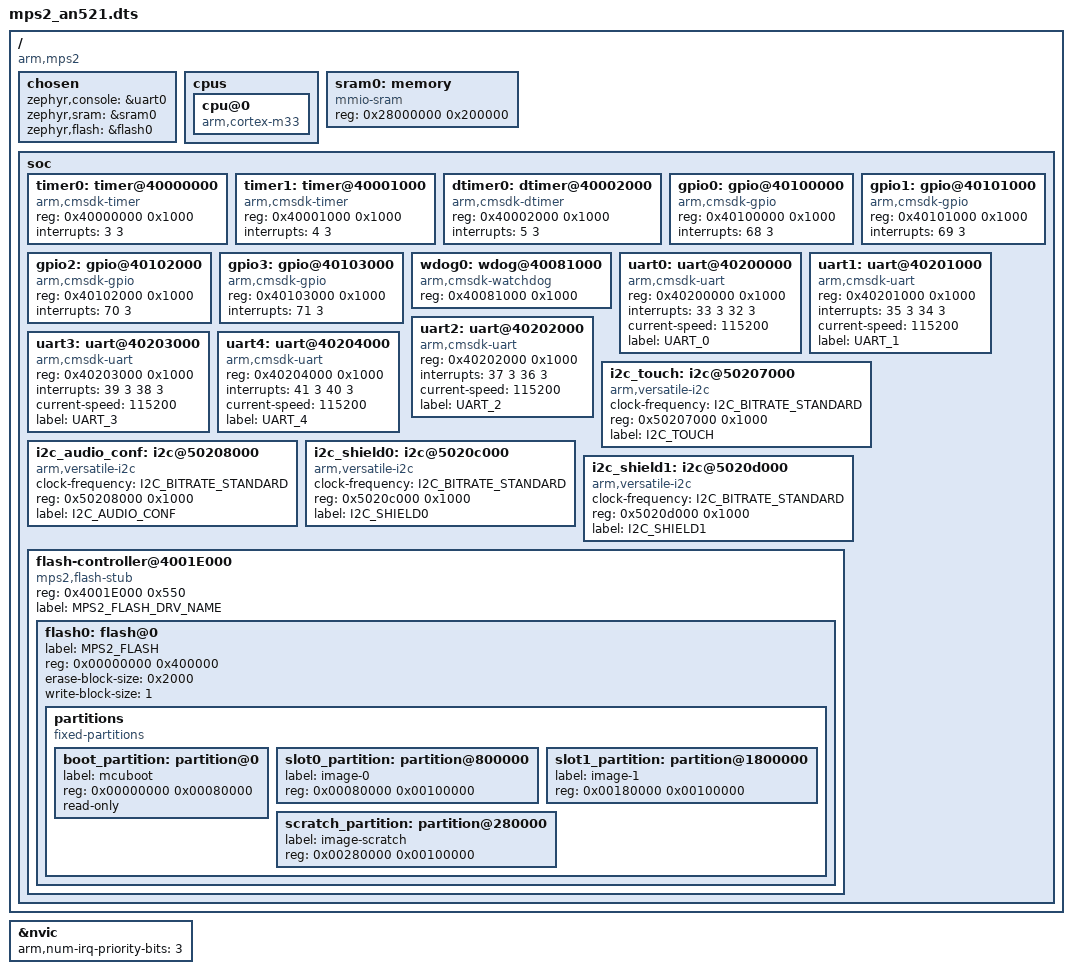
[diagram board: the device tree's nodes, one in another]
/dts-v1/;

#include <arm/armv8-m.dtsi>
#include <dt-bindings/i2c/i2c.h>

/ {
	compatible = "arm,mps2";
	#address-cells = <1>;
	#size-cells = <1>;

	chosen {
		zephyr,console = &uart0;
		zephyr,sram = &sram0;
		zephyr,flash = &flash0;
	};

	cpus {
		cpu@0 {
			compatible = "arm,cortex-m33";
		};
	};

	sram0: memory {
			compatible = "mmio-sram";
			reg = <0x28000000 0x200000>;
	};

	soc {
		timer0: timer@40000000 {
			compatible = "arm,cmsdk-timer";
			reg = <0x40000000 0x1000>;
			interrupts = <3 3>;
		};

		timer1: timer@40001000 {
			compatible = "arm,cmsdk-timer";
			reg = <0x40001000 0x1000>;
			interrupts = <4 3>;
		};

		dtimer0: dtimer@40002000 {
			compatible = "arm,cmsdk-dtimer";
			reg = <0x40002000 0x1000>;
			interrupts = <5 3>;
		};

		gpio0: gpio@40100000 {
			compatible = "arm,cmsdk-gpio";
			reg = <0x40100000 0x1000>;
			interrupts = <68 3>;
		};

		gpio1: gpio@40101000 {
			compatible = "arm,cmsdk-gpio";
			reg = <0x40101000 0x1000>;
			interrupts = <69 3>;
		};

		gpio2: gpio@40102000 {
			compatible = "arm,cmsdk-gpio";
			reg = <0x40102000 0x1000>;
			interrupts = <70 3>;
		};

		gpio3: gpio@40103000 {
			compatible = "arm,cmsdk-gpio";
			reg = <0x40103000 0x1000>;
			interrupts = <71 3>;
		};

		wdog0: wdog@40081000 {
			compatible = "arm,cmsdk-watchdog";
			reg = <0x40081000 0x1000>;
		};

		uart0: uart@40200000 {
			compatible = "arm,cmsdk-uart";
			reg = <0x40200000 0x1000>;
			interrupts = <33 3 32 3>;
			interrupt-names = "tx", "rx";
			current-speed = <115200>;
			label = "UART_0";
		};

		uart1: uart@40201000 {
			compatible = "arm,cmsdk-uart";
			reg = <0x40201000 0x1000>;
			interrupts = <35 3 34 3>;
			interrupt-names = "tx", "rx";
			current-speed = <115200>;
			label = "UART_1";
		};

		uart2: uart@40202000 {
			compatible = "arm,cmsdk-uart";
			reg = <0x40202000 0x1000>;
			interrupts = <37 3 36 3>;
			interrupt-names = "tx", "rx";
			current-speed = <115200>;
			label = "UART_2";
		};

		uart3: uart@40203000 {
			compatible = "arm,cmsdk-uart";
			reg = <0x40203000 0x1000>;
			interrupts = <39 3 38 3>;
			interrupt-names = "tx", "rx";
			current-speed = <115200>;
			label = "UART_3";
		};

		uart4: uart@40204000 {
			compatible = "arm,cmsdk-uart";
			reg = <0x40204000 0x1000>;
			interrupts = <41 3 40 3>;
			interrupt-names = "tx", "rx";
			current-speed = <115200>;
			label = "UART_4";
		};

		i2c_touch: i2c@50207000 {
			compatible = "arm,versatile-i2c";
			clock-frequency = <I2C_BITRATE_STANDARD>;
			#address-cells = <1>;
			#size-cells = <0>;
			reg = <0x50207000 0x1000>;
			label = "I2C_TOUCH";
		};

		i2c_audio_conf: i2c@50208000 {
			compatible = "arm,versatile-i2c";
			clock-frequency = <I2C_BITRATE_STANDARD>;
			#address-cells = <1>;
			#size-cells = <0>;
			reg = <0x50208000 0x1000>;
			label = "I2C_AUDIO_CONF";
		};

		i2c_shield0: i2c@5020c000 {
			compatible = "arm,versatile-i2c";
			clock-frequency = <I2C_BITRATE_STANDARD>;
			#address-cells = <1>;
			#size-cells = <0>;
			reg = <0x5020c000 0x1000>;
			label = "I2C_SHIELD0";
		};

		i2c_shield1: i2c@5020d000 {
			compatible = "arm,versatile-i2c";
			clock-frequency = <I2C_BITRATE_STANDARD>;
			#address-cells = <1>;
			#size-cells = <0>;
			reg = <0x5020d000 0x1000>;
			label = "I2C_SHIELD1";
		};

		flash-controller@4001E000 {
				compatible = "mps2,flash-stub";
				reg = <0x4001E000 0x550>;

				#address-cells = <1>;
				#size-cells = <1>;

				label="MPS2_FLASH_DRV_NAME";

				flash0: flash@0 {
					label = "MPS2_FLASH";
					reg = <0x00000000 0x400000>;
					erase-block-size = <0x2000>;
					write-block-size = <1>;
				};
		};
	};
};

&flash0 {
	/*
	 * For more information, see:
	 * http://docs.zephyrproject.org/devices/dts/flash_partitions.html
	 */
	partitions {
		compatible = "fixed-partitions";
		#address-cells = <1>;
		#size-cells = <1>;

		boot_partition: partition@0 {
			label = "mcuboot";
			reg = <0x00000000 0x00080000>;
			read-only;
		};
		slot0_partition: partition@800000 {
			label = "image-0";
			reg = <0x00080000 0x00100000>;
		};
		slot1_partition: partition@1800000 {
			label = "image-1";
			reg = <0x00180000 0x00100000>;
		};
		scratch_partition: partition@280000 {
			label = "image-scratch";
			reg = <0x00280000 0x00100000>;
		};
	};
};

&nvic {
	arm,num-irq-priority-bits = <3>;
};
